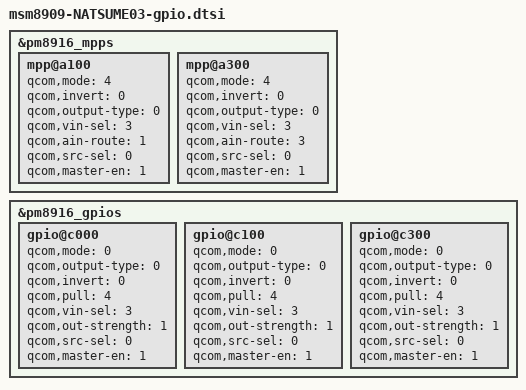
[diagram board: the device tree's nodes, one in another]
/*
 * This software is contributed or developed by KYOCERA Corporation.
 * (C) 2019 KYOCERA Corporation
 *
 * This program is free software; you can redistribute it and/or modify
 * it under the terms of the GNU General Public License version 2 and
 * only version 2 as published by the Free Software Foundation.
 *
 * This program is distributed in the hope that it will be useful,
 * but WITHOUT ANY WARRANTY; without even the implied warranty of
 * MERCHANTABILITY or FITNESS FOR A PARTICULAR PURPOSE.  See the
 * GNU General Public License for more details.
 */

&pm8916_mpps {
	mpp@a100 { /* MPP 2 */
		/* VCHG_MPP2 */
		status = "ok";
		qcom,mode = <4>;			/* QPNP_PIN_MODE_AIN */
		qcom,invert = <0>;			/* QPNP_PIN_INVERT_DISABLE */
		qcom,output-type = <0>;		/* QPNP_PIN_OUT_BUF_CMOS */
		qcom,vin-sel = <3>;			/* QPNP_PIN_VIN3 */
		qcom,ain-route = <1>;		/* QPNP_PIN_AIN_AMUX_CH6 */
		qcom,src-sel = <0>;			/* QPNP_PIN_SEL_FUNC_CONSTANT */
		qcom,master-en = <1>;		/* Enable */
	};

	mpp@a300 { /* MPP 4 */
		/* CAM_THERM */
		status = "ok";
		qcom,mode = <4>;			/* QPNP_PIN_MODE_AIN */
		qcom,invert = <0>;			/* QPNP_PIN_INVERT_DISABLE */
		qcom,output-type = <0>;		/* QPNP_PIN_OUT_BUF_CMOS */
		qcom,vin-sel = <3>;			/* QPNP_PIN_VIN3 */
		qcom,ain-route = <3>;		/* QPNP_PIN_AIN_AMUX_CH8 */
		qcom,src-sel = <0>;			/* QPNP_PIN_SEL_FUNC_CONSTANT */
		qcom,master-en = <1>;		/* Enable */
	};
};

&pm8916_gpios {
	gpio@c000 { /* GPIO 1 */
		/* N/C */
		status = "ok";
		qcom,mode = <0>;			/* QPNP_PIN_MODE_DIG_IN */
		qcom,output-type = <0>;		/* QPNP_PIN_OUT_BUF_CMOS */
		qcom,invert = <0>;			/* QPNP_PIN_INVERT_DISABLE */
		qcom,pull = <4>;			/* QPNP_PIN_PULL_DN */
		qcom,vin-sel = <3>;			/* QPNP_PIN_VIN3 */
		qcom,out-strength = <1>;	/* QPNP_PIN_OUT_STRENGTH_LOW */
		qcom,src-sel = <0>;			/* QPNP_PIN_SEL_FUNC_CONSTANT */
		qcom,master-en = <1>;		/* Enable */
	};

	gpio@c100 { /* GPIO 2 */
		/* N/C */
		status = "ok";
		qcom,mode = <0>;			/* QPNP_PIN_MODE_DIG_IN */
		qcom,output-type = <0>;		/* QPNP_PIN_OUT_BUF_CMOS */
		qcom,invert = <0>;			/* QPNP_PIN_INVERT_DISABLE */
		qcom,pull = <4>;			/* QPNP_PIN_PULL_DN */
		qcom,vin-sel = <3>;			/* QPNP_PIN_VIN3 */
		qcom,out-strength = <1>;	/* QPNP_PIN_OUT_STRENGTH_LOW */
		qcom,src-sel = <0>;			/* QPNP_PIN_SEL_FUNC_CONSTANT */
		qcom,master-en = <1>;		/* Enable */
	};

	gpio@c300 { /* GPIO 4 */
		/* SENS_SLEEP_CLK */
		status = "ok";
		qcom,mode = <0>;			/* QPNP_PIN_MODE_DIG_IN */
		qcom,output-type = <0>;		/* QPNP_PIN_OUT_BUF_CMOS */
		qcom,invert = <0>;			/* QPNP_PIN_INVERT_DISABLE */
		qcom,pull = <4>;			/* QPNP_PIN_PULL_DN */
		qcom,vin-sel = <3>;			/* QPNP_PIN_VIN3 */
		qcom,out-strength = <1>;	/* QPNP_PIN_OUT_STRENGTH_LOW */
		qcom,src-sel = <0>;			/* QPNP_PIN_SEL_FUNC_CONSTANT */
		qcom,master-en = <1>;		/* Enable */
	};
};
